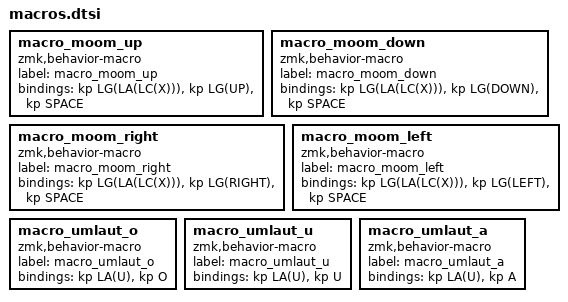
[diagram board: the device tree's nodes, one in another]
macro_moom_up: macro_moom_up{
compatible = "zmk,behavior-macro";
label = "macro_moom_up";
#binding-cells = <0>;
bindings = <&kp LG(LA(LC(X)))>, <&kp LG(UP)>, <&kp SPACE>;
};
macro_moom_down: macro_moom_down{
compatible = "zmk,behavior-macro";
label = "macro_moom_down";
#binding-cells = <0>;
bindings = <&kp LG(LA(LC(X)))>, <&kp LG(DOWN)>, <&kp SPACE>;
};
macro_moom_right: macro_moom_right{
compatible = "zmk,behavior-macro";
label = "macro_moom_right";
#binding-cells = <0>;
bindings = <&kp LG(LA(LC(X)))>, <&kp LG(RIGHT)>, <&kp SPACE>;
};
macro_moom_left: macro_moom_left{
compatible = "zmk,behavior-macro";
label = "macro_moom_left";
#binding-cells = <0>;
bindings = <&kp LG(LA(LC(X)))>, <&kp LG(LEFT)>, <&kp SPACE>;
};
macro_umlaut_o: macro_umlaut_o{
compatible = "zmk,behavior-macro";
label = "macro_umlaut_o";
#binding-cells = <0>;
bindings = <&kp LA(U)>, <&kp O>;
};
macro_umlaut_u: macro_umlaut_u{
compatible = "zmk,behavior-macro";
label = "macro_umlaut_u";
#binding-cells = <0>;
bindings = <&kp LA(U)>, <&kp U>;
};
macro_umlaut_a: macro_umlaut_a{
compatible = "zmk,behavior-macro";
label = "macro_umlaut_a";
#binding-cells = <0>;
bindings = <&kp LA(U)>, <&kp A>;
};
